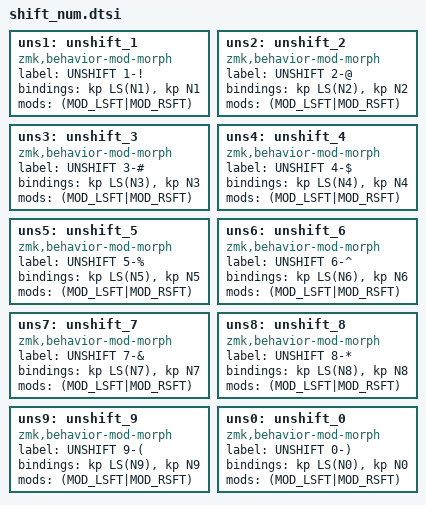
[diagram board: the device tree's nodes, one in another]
uns1: unshift_1 {
  compatible = "zmk,behavior-mod-morph";
  label = "UNSHIFT 1-!";
  bindings = <&kp LS(N1)>, <&kp N1>;
  #binding-cells = <0>;
  mods = <(MOD_LSFT|MOD_RSFT)>;
};

uns2: unshift_2 {
  compatible = "zmk,behavior-mod-morph";
  label = "UNSHIFT 2-@";
  bindings = <&kp LS(N2)>, <&kp N2>;
  #binding-cells = <0>;
  mods = <(MOD_LSFT|MOD_RSFT)>;
};

uns3: unshift_3 {
  compatible = "zmk,behavior-mod-morph";
  label = "UNSHIFT 3-#";
  bindings = <&kp LS(N3)>, <&kp N3>;
  #binding-cells = <0>;
  mods = <(MOD_LSFT|MOD_RSFT)>;
};

uns4: unshift_4 {
  compatible = "zmk,behavior-mod-morph";
  label = "UNSHIFT 4-$";
  bindings = <&kp LS(N4)>, <&kp N4>;
  #binding-cells = <0>;
  mods = <(MOD_LSFT|MOD_RSFT)>;
};

uns5: unshift_5 {
  compatible = "zmk,behavior-mod-morph";
  label = "UNSHIFT 5-%";
  bindings = <&kp LS(N5)>, <&kp N5>;
  #binding-cells = <0>;
  mods = <(MOD_LSFT|MOD_RSFT)>;
};

uns6: unshift_6 {
  compatible = "zmk,behavior-mod-morph";
  label = "UNSHIFT 6-^";
  bindings = <&kp LS(N6)>, <&kp N6>;
  #binding-cells = <0>;
  mods = <(MOD_LSFT|MOD_RSFT)>;
};

uns7: unshift_7 {
  compatible = "zmk,behavior-mod-morph";
  label = "UNSHIFT 7-&";
  bindings = <&kp LS(N7)>, <&kp N7>;
  #binding-cells = <0>;
  mods = <(MOD_LSFT|MOD_RSFT)>;
};

uns8: unshift_8 {
  compatible = "zmk,behavior-mod-morph";
  label = "UNSHIFT 8-*";
  bindings = <&kp LS(N8)>, <&kp N8>;
  #binding-cells = <0>;
  mods = <(MOD_LSFT|MOD_RSFT)>;
};

uns9: unshift_9 {
  compatible = "zmk,behavior-mod-morph";
  label = "UNSHIFT 9-(";
  bindings = <&kp LS(N9)>, <&kp N9>;
  #binding-cells = <0>;
  mods = <(MOD_LSFT|MOD_RSFT)>;
};

uns0: unshift_0 {
  compatible = "zmk,behavior-mod-morph";
  label = "UNSHIFT 0-)";
  bindings = <&kp LS(N0)>, <&kp N0>;
  #binding-cells = <0>;
  mods = <(MOD_LSFT|MOD_RSFT)>;
};
